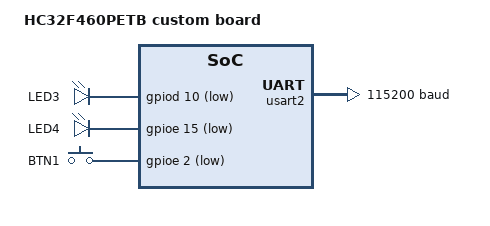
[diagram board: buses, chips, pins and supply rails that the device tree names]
/*
 * SPDX-License-Identifier: Apache-2.0
 *
 * HC32F460PETB board devicetree
 *
 * Hardware:
 *   LED3: PD10 (active-low)
 *   LED4: PE15 (active-low)
 *   BTN0: PA3  (active-low, internal pull-up)
 *   BTN1: PE2  (active-low, internal pull-up)
 *   USART2: PA2(TX)/PA3(RX), 115200, DAPLink VCP
 */

/dts-v1/;
#include <arm/hdsc/hc32f460.dtsi>
#include <zephyr/dt-bindings/input/input-event-codes.h>

/ {
	model = "HC32F460PETB custom board";
	compatible = "hdsc,hc32f460petb";

	chosen {
		zephyr,console = &usart2;
		zephyr,shell-uart = &usart2;
		zephyr,sram = &sram0;
		zephyr,flash = &flash0;
	};

	leds: leds {
		compatible = "gpio-leds";

		led3: led_3 {
			gpios = <&gpiod 10 GPIO_ACTIVE_LOW>;
			label = "LED3";
		};

		led4: led_4 {
			gpios = <&gpioe 15 GPIO_ACTIVE_LOW>;
			label = "LED4";
		};
	};

	gpio_keys {
		compatible = "gpio-keys";

		btn1: button_1 {
			gpios = <&gpioe 2 (GPIO_ACTIVE_LOW | GPIO_PULL_UP)>;
			label = "BTN1";
			zephyr,code = <INPUT_KEY_0>;
		};
	};

	aliases {
		led0 = &led3;
		led1 = &led4;
		sw0 = &btn1;
	};
};

&gpioa {
	status = "okay";
};

&gpiod {
	status = "okay";
};

&gpioe {
	status = "okay";
};

&usart2 {
	current-speed = <115200>;
	status = "okay";
};
